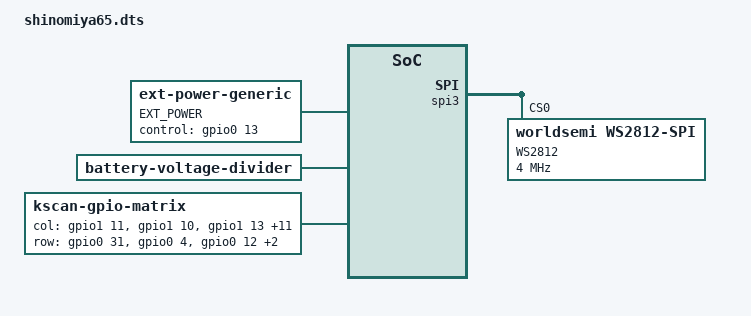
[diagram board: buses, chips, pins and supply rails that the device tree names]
/*
 * Copyright (c) 2021 The ZMK Contributors
 *
 * SPDX-License-Identifier: MIT
 */

/dts-v1/;
#include "shinomiya65.dtsi"
#include <dt-bindings/led/led.h>

/ {
    chosen {
        zmk,battery = &vbatt;
        zmk,kscan = &kscan0;
        zmk,underglow = &led_strip;
    };

    ext-power {
        compatible = "zmk,ext-power-generic";
        label = "EXT_POWER";
        control-gpios = <&gpio0 13 GPIO_ACTIVE_HIGH>;
        init-delay-ms = <50>;
    };

    vbatt: vbatt {
        compatible = "zmk,battery-voltage-divider";
        label = "BATTERY";
    };

    kscan0: kscan_0 {
        compatible = "zmk,kscan-gpio-matrix";
        label = "KSCAN";
        diode-direction = "col2row";

        col-gpios
            = <&gpio1 11 GPIO_ACTIVE_HIGH>
            , <&gpio1 10 GPIO_ACTIVE_HIGH>
            , <&gpio1 13 GPIO_ACTIVE_HIGH>
            , <&gpio0 29 GPIO_ACTIVE_HIGH>
            , <&gpio0 30 GPIO_ACTIVE_HIGH>
            , <&gpio0 23 GPIO_ACTIVE_HIGH>
            , <&gpio0 02 GPIO_ACTIVE_HIGH>
            , <&gpio0 21 GPIO_ACTIVE_HIGH>
            , <&gpio0 22 GPIO_ACTIVE_HIGH>
            , <&gpio1 0 GPIO_ACTIVE_HIGH>
            , <&gpio1 3 GPIO_ACTIVE_HIGH>
            , <&gpio1 6 GPIO_ACTIVE_HIGH>
            , <&gpio0 9 GPIO_ACTIVE_HIGH>
            , <&gpio0 10 GPIO_ACTIVE_HIGH>
            ;

        row-gpios
            = <&gpio0 31 (GPIO_ACTIVE_HIGH | GPIO_PULL_DOWN)>
            , <&gpio0 4 (GPIO_ACTIVE_HIGH | GPIO_PULL_DOWN)>
            , <&gpio0 12 (GPIO_ACTIVE_HIGH | GPIO_PULL_DOWN)>
            , <&gpio1 4 (GPIO_ACTIVE_HIGH | GPIO_PULL_DOWN)>
            , <&gpio0 3 (GPIO_ACTIVE_HIGH | GPIO_PULL_DOWN)>
            ;
    };
};

&spi3 {
	compatible = "nordic,nrf-spim";
	status = "okay";
	pinctrl-0 = <&spi3_default>;
	pinctrl-1 = <&spi3_sleep>;
	pinctrl-names = "default", "sleep";
	led_strip: ws2812@0 {
		compatible = "worldsemi,ws2812-spi";
		label = "WS2812";
		/* SPI */
		reg = <0>; /* ignored, but necessary for SPI bindings */
		spi-max-frequency = <4000000>;
		/* WS2812 */
		chain-length = <63>; /* LED strip length */
		spi-one-frame = <0x70>;
		spi-zero-frame = <0x40>;
		color-mapping = <LED_COLOR_ID_GREEN LED_COLOR_ID_RED LED_COLOR_ID_BLUE>;
	};
};
